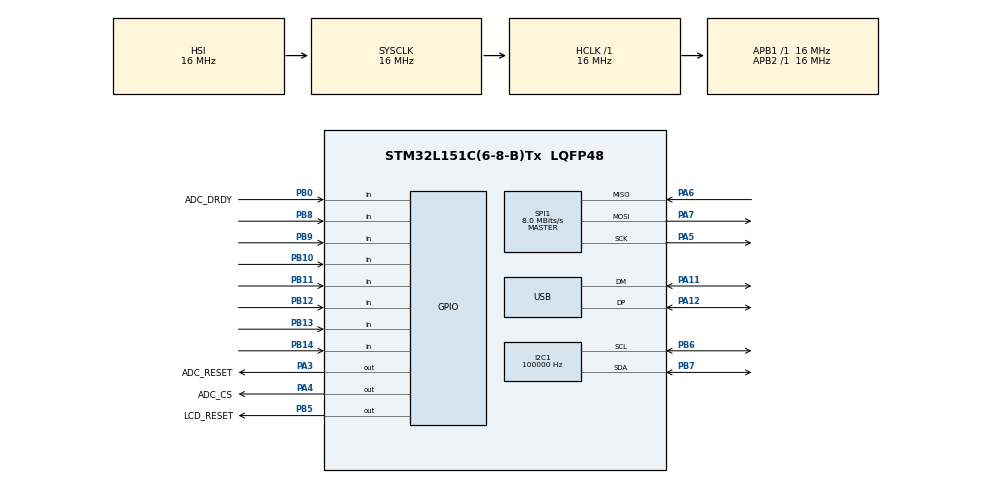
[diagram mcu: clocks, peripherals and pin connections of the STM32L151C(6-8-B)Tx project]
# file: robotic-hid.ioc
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FREERTOS.Tasks01=defaultTask,24,128,StartDefaultTask,Default,NULL,Dynamic,NULL,NULL
FREERTOS.configUSE_NEWLIB_REENTRANT=1
I2C1.ClockSpeed=100000
Mcu.Family=STM32L1
Mcu.Name=STM32L151C(6-8-B)Tx
Mcu.Package=LQFP48
NVIC.PriorityGroup=NVIC_PRIORITYGROUP_4
NVIC.TIM2_IRQn=true\:15\:0\:false\:false\:true\:false\:false\:true\:true
NVIC.TimeBase=TIM2_IRQn
NVIC.TimeBaseIP=TIM2
NVIC.USB_LP_IRQn=true\:5\:0\:false\:false\:true\:true\:false\:true\:true
PA11.Mode=Device
PA11.Signal=USB_DM
PA12.Mode=Device
PA12.Signal=USB_DP
PA13.Mode=Trace_Asynchronous_SW
PA13.Signal=SYS_JTMS-SWDIO
PA14.Mode=Trace_Asynchronous_SW
PA14.Signal=SYS_JTCK-SWCLK
PA3.GPIO_Label=ADC_RESET
PA3.Signal=GPIO_Output
PA4.GPIO_Label=ADC_CS
PA4.Signal=GPIO_Output
PA5.Mode=Full_Duplex_Master
PA5.Signal=SPI1_SCK
PA6.Mode=Full_Duplex_Master
PA6.Signal=SPI1_MISO
PA7.Mode=Full_Duplex_Master
PA7.Signal=SPI1_MOSI
PB0.GPIO_Label=ADC_DRDY
PB0.Signal=GPIO_Input
PB10.Signal=GPIO_Input
PB11.Signal=GPIO_Input
PB12.Signal=GPIO_Input
PB13.Signal=GPIO_Input
PB14.Signal=GPIO_Input
PB3.Mode=Trace_Asynchronous_SW
PB3.Signal=SYS_JTDO-TRACESWO
PB5.GPIO_Label=LCD_RESET
PB5.Signal=GPIO_Output
PB6.Mode=I2C
PB6.Signal=I2C1_SCL
PB7.Mode=I2C
PB7.Signal=I2C1_SDA
PB8.Signal=GPIO_Input
PB9.Signal=GPIO_Input
PH0-OSC_IN.Mode=HSE-External-Clock-Source
PH0-OSC_IN.Signal=RCC_OSC_IN
ProjectManager.HeapSize=0x200
ProjectManager.StackSize=0x400
ProjectManager.TargetToolchain=STM32CubeIDE
RCC.48MHZClocksFreq_Value=48000000
RCC.AHBFreq_Value=16000000
RCC.APB1Freq_Value=16000000
RCC.APB1TimFreq_Value=16000000
RCC.APB2Freq_Value=16000000
RCC.APB2TimFreq_Value=16000000
RCC.HCLKFreq_Value=16000000
RCC.HSE_VALUE=24000000
RCC.HSI_VALUE=16000000
RCC.LSE_VALUE=32768
RCC.MSI_VALUE=2097000
RCC.PLLMUL=RCC_PLL_MUL4
RCC.SYSCLKFreq_VALUE=16000000
RCC.SYSCLKSource=RCC_SYSCLKSOURCE_HSI
RCC.VCOOutputFreq_Value=96000000
SPI1.CLKPhase=SPI_PHASE_2EDGE
SPI1.CalculateBaudRate=8.0 MBits/s
SPI1.Direction=SPI_DIRECTION_2LINES
SPI1.Mode=SPI_MODE_MASTER
SPI1.VirtualType=VM_MASTER
USB_DEVICE.CLASS_NAME_FS=HID
USB_DEVICE.PRODUCT_STRING_HID_FS=Kale Robotic HID
USB_DEVICE.VirtualMode=Hid
USB_DEVICE.VirtualModeFS=Hid_FS
VP_FREERTOS_VS_CMSIS_V2.Mode=CMSIS_V2
VP_SYS_VS_tim2.Mode=TIM2
VP_USB_DEVICE_VS_USB_DEVICE_HID_FS.Mode=HID_FS
board=custom

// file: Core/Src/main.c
/* USER CODE BEGIN Header */
/**
  ******************************************************************************
  * @file           : main.c
  * @brief          : Main program body
  ******************************************************************************
  * @attention
  *
  * <h2><center>&copy; Copyright (c) 2022 STMicroelectronics.
  * All rights reserved.</center></h2>
  *
  * This software component is licensed by ST under BSD 3-Clause license,
  * the "License"; You may not use this file except in compliance with the
  * License. You may obtain a copy of the License at:
  *                        opensource.org/licenses/BSD-3-Clause
  *
  ******************************************************************************
  */
/* USER CODE END Header */
#include "main.h"
#include "cmsis_os.h"
#include "i2c.h"
#include "spi.h"
#include "usb_device.h"
#include "gpio.h"
#include "usb_device.h"

/* USER CODE BEGIN Includes */
#include "application.h"
/* USER CODE END Includes */

void SystemClock_Config(void);
void MX_FREERTOS_Init(void);

int main(void)
{

  /* MCU Configuration--------------------------------------------------------*/

  /* Reset of all peripherals, Initializes the Flash interface and the Systick. */
  HAL_Init();

  /* USER CODE BEGIN Init */
  osKernelInitialize();  /* Call init function for freertos objects (in freertos.c) */
  MX_FREERTOS_Init();

  /* USER CODE END Init */

  /* Configure the system clock */
  SystemClock_Config();

  /* Initialize all configured peripherals */
  MX_GPIO_Init();
  MX_I2C1_Init();
  MX_SPI1_Init();

  /* Init scheduler */

  //Using CMSIS FreeRTOS API to create tasks for joystick and LCD update:
  //Thread attributes: priority, stack size, and task function

  //Ignore Wincompatible-pointer-types warning
  #pragma GCC diagnostic push
  #pragma GCC diagnostic ignored "-Wincompatible-pointer-types"

  osThreadAttr_t joystick_thread_attr = {
    .name = "Joystick",
    .priority = (osPriority_t)40,
    .stack_size = 512
  };
  osThreadNew(joystick_task, NULL, &joystick_thread_attr);\

  osThreadAttr_t lcd_thread_attr = {
    .name = "LCD",
    .priority = (osPriority_t)20,
    .stack_size = 512
  };

  osThreadNew(lcd_task, NULL, &lcd_thread_attr);
  #pragma GCC diagnostic pop

  /* Start scheduler */
  osKernelStart();

  /* We should never get here as control is now taken by the scheduler */
  /* Infinite loop */
  while (1)
  {

  }
}

void SystemClock_Config(void)
{
  RCC_OscInitTypeDef RCC_OscInitStruct = {0};
  RCC_ClkInitTypeDef RCC_ClkInitStruct = {0};

  /** Configure the main internal regulator output voltage
  */
  __HAL_PWR_VOLTAGESCALING_CONFIG(PWR_REGULATOR_VOLTAGE_SCALE1);
  /** Initializes the RCC Oscillators according to the specified parameters
  * in the RCC_OscInitTypeDef structure.
  */
  RCC_OscInitStruct.OscillatorType = RCC_OSCILLATORTYPE_HSI|RCC_OSCILLATORTYPE_HSE;
  RCC_OscInitStruct.HSEState = RCC_HSE_BYPASS;
  RCC_OscInitStruct.HSIState = RCC_HSI_ON;
  RCC_OscInitStruct.HSICalibrationValue = RCC_HSICALIBRATION_DEFAULT;
  RCC_OscInitStruct.PLL.PLLState = RCC_PLL_ON;
  RCC_OscInitStruct.PLL.PLLSource = RCC_PLLSOURCE_HSE;
  RCC_OscInitStruct.PLL.PLLMUL = RCC_PLL_MUL4;
  RCC_OscInitStruct.PLL.PLLDIV = RCC_PLL_DIV2;
  if (HAL_RCC_OscConfig(&RCC_OscInitStruct) != HAL_OK)
  {
    Error_Handler();
  }
  /** Initializes the CPU, AHB and APB buses clocks
  */
  RCC_ClkInitStruct.ClockType = RCC_CLOCKTYPE_HCLK|RCC_CLOCKTYPE_SYSCLK
                              |RCC_CLOCKTYPE_PCLK1|RCC_CLOCKTYPE_PCLK2;
  RCC_ClkInitStruct.SYSCLKSource = RCC_SYSCLKSOURCE_HSI;
  RCC_ClkInitStruct.AHBCLKDivider = RCC_SYSCLK_DIV1;
  RCC_ClkInitStruct.APB1CLKDivider = RCC_HCLK_DIV1;
  RCC_ClkInitStruct.APB2CLKDivider = RCC_HCLK_DIV1;

  if (HAL_RCC_ClockConfig(&RCC_ClkInitStruct, FLASH_LATENCY_0) != HAL_OK)
  {
    Error_Handler();
  }
}

void HAL_TIM_PeriodElapsedCallback(TIM_HandleTypeDef *htim)
{
  if (htim->Instance == TIM2) {
    HAL_IncTick();
  }
}

void Error_Handler(void)
{
  __disable_irq();
  while (1)
  {
  }
}

/************************ (C) COPYRIGHT STMicroelectronics *****END OF FILE****/

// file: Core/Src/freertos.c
/* USER CODE BEGIN Header */
/**
  ******************************************************************************
  * File Name          : freertos.c
  * Description        : Code for freertos applications
  ******************************************************************************
  * @attention
  *
  * <h2><center>&copy; Copyright (c) 2022 STMicroelectronics.
  * All rights reserved.</center></h2>
  *
  * This software component is licensed by ST under Ultimate Liberty license
  * SLA0044, the "License"; You may not use this file except in compliance with
  * the License. You may obtain a copy of the License at:
  *                             www.st.com/SLA0044
  *
  ******************************************************************************
  */
/* USER CODE END Header */

#include "FreeRTOS.h"
#include "task.h"
#include "main.h"
#include "cmsis_os.h"

/* Definitions for defaultTask */
osThreadId_t defaultTaskHandle;
const osThreadAttr_t defaultTask_attributes = {
  .name = "defaultTask",
  .stack_size = 128 * 4,
  .priority = (osPriority_t) osPriorityNormal,
};

void StartDefaultTask(void *argument);

extern void MX_USB_DEVICE_Init(void);
void MX_FREERTOS_Init(void); /* (MISRA C 2004 rule 8.1) */

void MX_FREERTOS_Init(void) {

  /* Create the thread(s) */
  /* creation of defaultTask */
  defaultTaskHandle = osThreadNew(StartDefaultTask, NULL, &defaultTask_attributes);

}

void StartDefaultTask(void *argument)
{
  /* init code for USB_DEVICE */
  MX_USB_DEVICE_Init();
  for(;;)
  {
    osDelay(1);
  }
}

/************************ (C) COPYRIGHT STMicroelectronics *****END OF FILE****/
